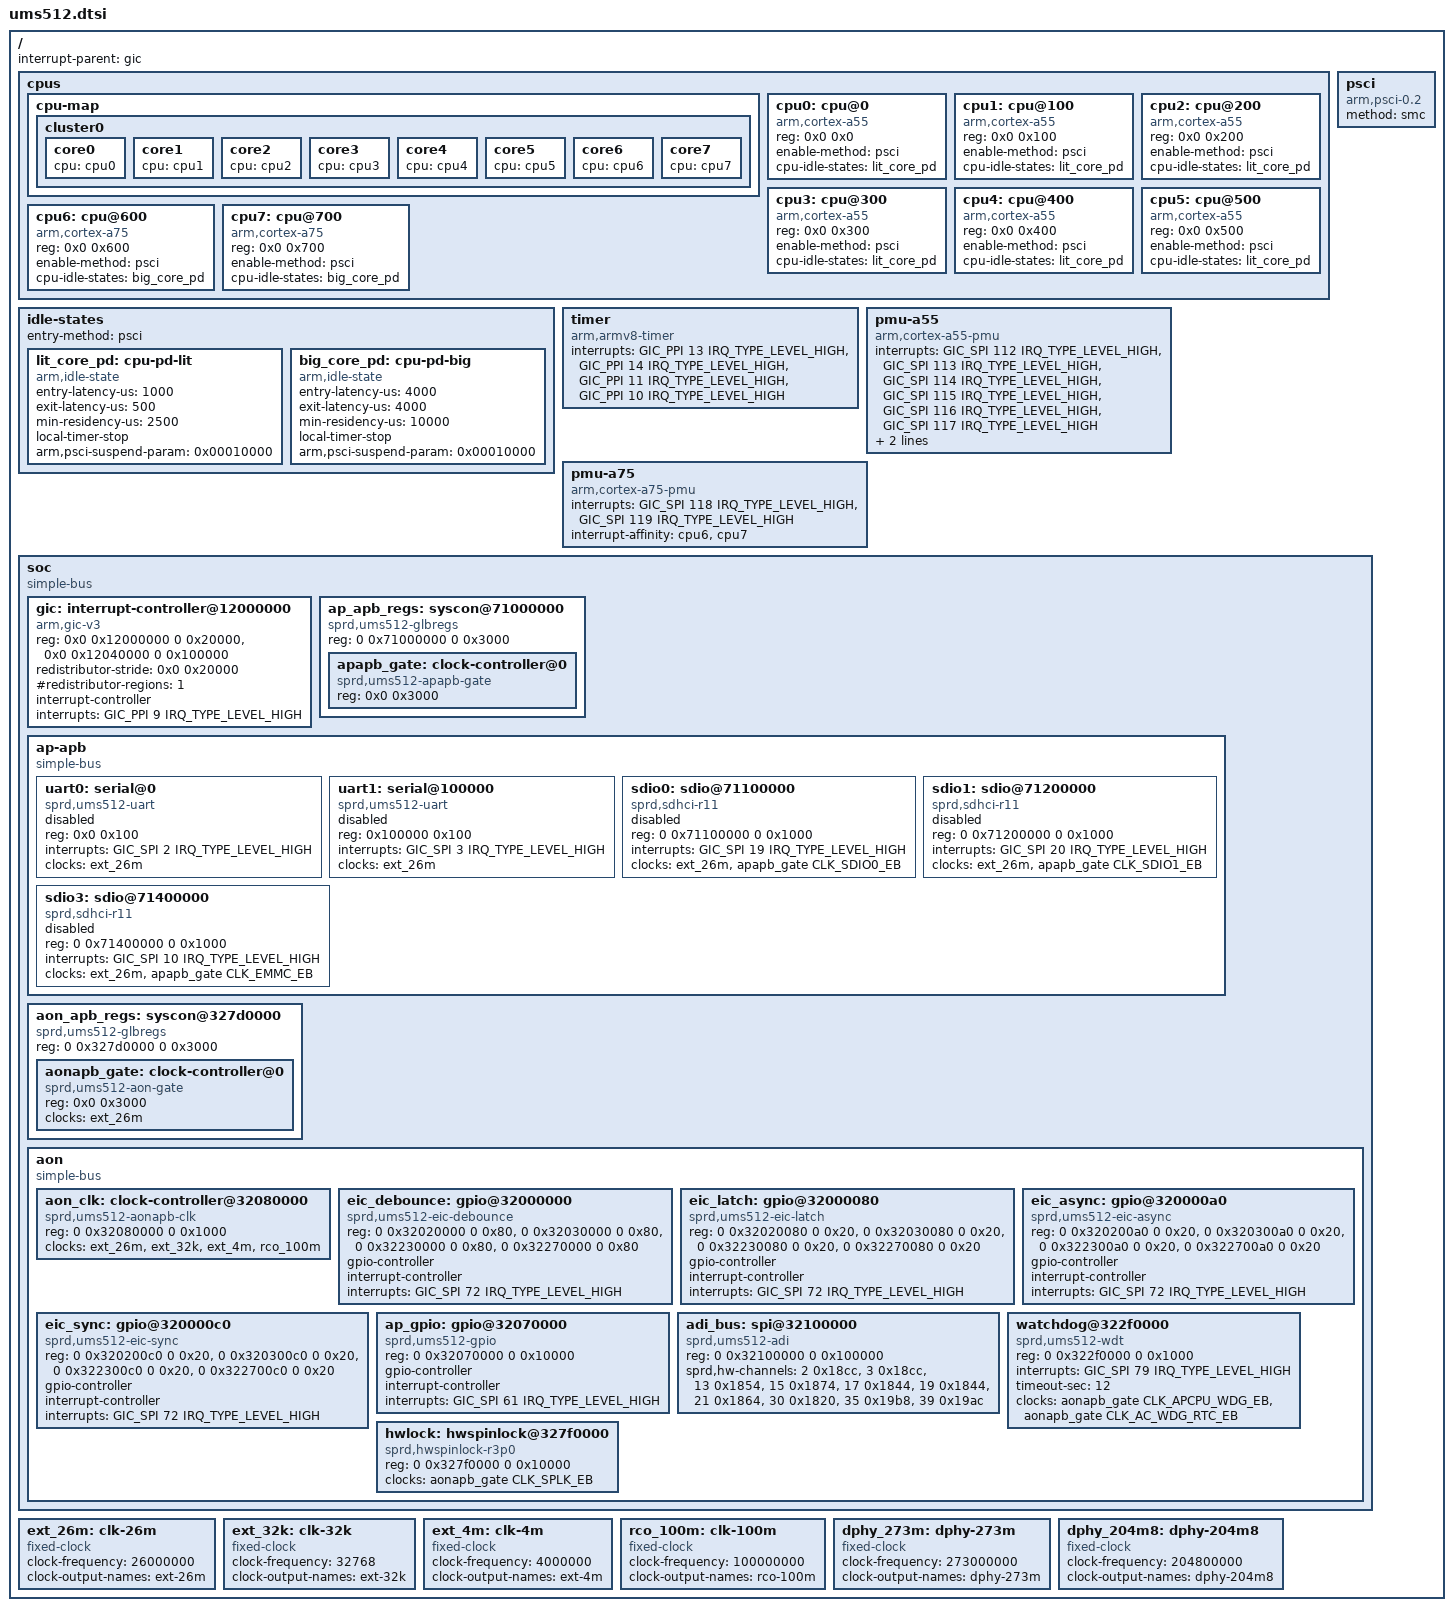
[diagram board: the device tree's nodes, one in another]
// SPDX-License-Identifier: (GPL-2.0 OR MIT)
/*
 * Unisoc UMS512 DTS file
 *
 * Copyright (C) 2025 Vladimir Panferov
 */

#include <dt-bindings/clock/sprd,ums512-clk.h>
#include <dt-bindings/gpio/gpio.h>
#include <dt-bindings/interrupt-controller/arm-gic.h>

/ {
	interrupt-parent = <&gic>;
	#address-cells = <2>;
	#size-cells = <2>;

	cpus {
		#address-cells = <2>;
		#size-cells = <0>;

		cpu-map {
			cluster0 {
				core0 {
					cpu = <&cpu0>;
				};
				core1 {
					cpu = <&cpu1>;
				};
				core2 {
					cpu = <&cpu2>;
				};
				core3 {
					cpu = <&cpu3>;
				};
				core4 {
					cpu = <&cpu4>;
				};
				core5 {
					cpu = <&cpu5>;
				};
				core6 {
					cpu = <&cpu6>;
				};
				core7 {
					cpu = <&cpu7>;
				};
			};
		};

		cpu0: cpu@0 {
			device_type = "cpu";
			compatible = "arm,cortex-a55";
			reg = <0x0 0x0>;
			enable-method = "psci";
			cpu-idle-states = <&lit_core_pd>;
		};

		cpu1: cpu@100 {
			device_type = "cpu";
			compatible = "arm,cortex-a55";
			reg = <0x0 0x100>;
			enable-method = "psci";
			cpu-idle-states = <&lit_core_pd>;
		};

		cpu2: cpu@200 {
			device_type = "cpu";
			compatible = "arm,cortex-a55";
			reg = <0x0 0x200>;
			enable-method = "psci";
			cpu-idle-states = <&lit_core_pd>;
		};

		cpu3: cpu@300 {
			device_type = "cpu";
			compatible = "arm,cortex-a55";
			reg = <0x0 0x300>;
			enable-method = "psci";
			cpu-idle-states = <&lit_core_pd>;
		};

		cpu4: cpu@400 {
			device_type = "cpu";
			compatible = "arm,cortex-a55";
			reg = <0x0 0x400>;
			enable-method = "psci";
			cpu-idle-states = <&lit_core_pd>;
		};

		cpu5: cpu@500 {
			device_type = "cpu";
			compatible = "arm,cortex-a55";
			reg = <0x0 0x500>;
			enable-method = "psci";
			cpu-idle-states = <&lit_core_pd>;
		};

		cpu6: cpu@600 {
			device_type = "cpu";
			compatible = "arm,cortex-a75";
			reg = <0x0 0x600>;
			enable-method = "psci";
			cpu-idle-states = <&big_core_pd>;
		};

		cpu7: cpu@700 {
			device_type = "cpu";
			compatible = "arm,cortex-a75";
			reg = <0x0 0x700>;
			enable-method = "psci";
			cpu-idle-states = <&big_core_pd>;
		};
	};

	idle-states {
		entry-method = "psci";
		lit_core_pd: cpu-pd-lit {
			compatible = "arm,idle-state";
			entry-latency-us = <1000>;
			exit-latency-us = <500>;
			min-residency-us = <2500>;
			local-timer-stop;
			arm,psci-suspend-param = <0x00010000>;
		};

		big_core_pd: cpu-pd-big {
			compatible = "arm,idle-state";
			entry-latency-us = <4000>;
			exit-latency-us = <4000>;
			min-residency-us = <10000>;
			local-timer-stop;
			arm,psci-suspend-param = <0x00010000>;
		};
	};

	psci {
		compatible = "arm,psci-0.2";
		method = "smc";
	};

	timer {
		compatible = "arm,armv8-timer";
		interrupts = <GIC_PPI 13 IRQ_TYPE_LEVEL_HIGH>, /* Physical Secure PPI */
			     <GIC_PPI 14 IRQ_TYPE_LEVEL_HIGH>, /* Physical Non-Secure PPI */
			     <GIC_PPI 11 IRQ_TYPE_LEVEL_HIGH>, /* Virtual PPI */
			     <GIC_PPI 10 IRQ_TYPE_LEVEL_HIGH>; /* Hipervisor PPI */
	};

	pmu-a55 {
		compatible = "arm,cortex-a55-pmu";
		interrupts = <GIC_SPI 112 IRQ_TYPE_LEVEL_HIGH>,
			     <GIC_SPI 113 IRQ_TYPE_LEVEL_HIGH>,
			     <GIC_SPI 114 IRQ_TYPE_LEVEL_HIGH>,
			     <GIC_SPI 115 IRQ_TYPE_LEVEL_HIGH>,
			     <GIC_SPI 116 IRQ_TYPE_LEVEL_HIGH>,
			     <GIC_SPI 117 IRQ_TYPE_LEVEL_HIGH>;
		interrupt-affinity = <&cpu0>, <&cpu1>, <&cpu2>, <&cpu3>, <&cpu4>, <&cpu5>;
	};

	pmu-a75 {
		compatible = "arm,cortex-a75-pmu";
		interrupts = <GIC_SPI 118 IRQ_TYPE_LEVEL_HIGH>,
			     <GIC_SPI 119 IRQ_TYPE_LEVEL_HIGH>;
		interrupt-affinity = <&cpu6>, <&cpu7>;
	};

	soc: soc {
		compatible = "simple-bus";
		ranges;
		#address-cells = <2>;
		#size-cells = <2>;

		gic: interrupt-controller@12000000 {
			compatible = "arm,gic-v3";
			reg = <0x0 0x12000000 0 0x20000>,	/* GICD */
			      <0x0 0x12040000 0 0x100000>;	/* GICR */
			#interrupt-cells = <3>;
			#address-cells = <2>;
			#size-cells = <2>;
			redistributor-stride = <0x0 0x20000>;	/* 128KB stride */
			#redistributor-regions = <1>;
			interrupt-controller;
			interrupts = <GIC_PPI 9 IRQ_TYPE_LEVEL_HIGH>;
		};

		ap_apb_regs: syscon@71000000 {
			compatible = "sprd,ums512-glbregs", "syscon", "simple-mfd";
			reg = <0 0x71000000 0 0x3000>;
			#address-cells = <1>;
			#size-cells = <1>;
			ranges = <0 0 0x71000000 0x3000>;

			apapb_gate: clock-controller@0 {
				compatible = "sprd,ums512-apapb-gate";
				reg = <0x0 0x3000>;
				#clock-cells = <1>;
			};
		};

		ap-apb {
			compatible = "simple-bus";
			#address-cells = <2>;
			#size-cells = <2>;
			ranges;

			uart0: serial@0 {
				compatible = "sprd,ums512-uart",
					     "sprd,sc9836-uart";
				reg = <0x0 0x100>;
				interrupts = <GIC_SPI 2 IRQ_TYPE_LEVEL_HIGH>;
				clocks = <&ext_26m>;
				status = "disabled";
			};

			uart1: serial@100000 {
				compatible = "sprd,ums512-uart",
					     "sprd,sc9836-uart";
				reg = <0x100000 0x100>;
				interrupts = <GIC_SPI 3 IRQ_TYPE_LEVEL_HIGH>;
				clocks = <&ext_26m>;
				status = "disabled";
			};

			sdio0: sdio@71100000 {
				compatible = "sprd,sdhci-r11";
				reg = <0 0x71100000 0 0x1000>;
				interrupts = <GIC_SPI 19 IRQ_TYPE_LEVEL_HIGH>;
				clocks = <&ext_26m>, <&apapb_gate CLK_SDIO0_EB>;
				clock-names = "sdio", "enable";
				status = "disabled";
			};

			sdio1: sdio@71200000 {
				compatible = "sprd,sdhci-r11";
				reg = <0 0x71200000 0 0x1000>;
				interrupts = <GIC_SPI 20 IRQ_TYPE_LEVEL_HIGH>;
				clocks = <&ext_26m>, <&apapb_gate CLK_SDIO1_EB>;
				clock-names = "sdio", "enable";
				status = "disabled";
			};

			sdio3: sdio@71400000 {
				compatible = "sprd,sdhci-r11";
				reg = <0 0x71400000 0 0x1000>;
				interrupts = <GIC_SPI 10 IRQ_TYPE_LEVEL_HIGH>;
				clocks = <&ext_26m>, <&apapb_gate CLK_EMMC_EB>;
				clock-names = "sdio", "enable";
				status = "disabled";
			};
		};

		aon_apb_regs: syscon@327d0000 {
			compatible = "sprd,ums512-glbregs", "syscon",
				     "simple-mfd";
			reg = <0 0x327d0000 0 0x3000>;
			#address-cells = <1>;
			#size-cells = <1>;
			ranges = <0 0 0x327d0000 0x3000>;

			aonapb_gate: clock-controller@0 {
				compatible = "sprd,ums512-aon-gate";
				reg = <0x0 0x3000>;
				clocks = <&ext_26m>;
				clock-names = "ext-26m";
				#clock-cells = <1>;
				#reset-cells = <1>;
			};
		};

		aon {
			compatible = "simple-bus";
			#address-cells = <2>;
			#size-cells = <2>;
			ranges;

			aon_clk: clock-controller@32080000 {
				compatible = "sprd,ums512-aonapb-clk";
				reg = <0 0x32080000 0 0x1000>;
				clocks = <&ext_26m>, <&ext_32k>,
					 <&ext_4m>, <&rco_100m>;
				clock-names = "ext-26m", "ext-32k",
					      "ext-4m", "rco-100m";
				#clock-cells = <1>;
			};

			eic_debounce: gpio@32000000 {
				compatible = "sprd,ums512-eic-debounce", "sprd,sc9860-eic-debounce";
				reg = <0 0x32020000 0 0x80>,
				      <0 0x32030000 0 0x80>,
				      <0 0x32230000 0 0x80>,
				      <0 0x32270000 0 0x80>;
				gpio-controller;
				#gpio-cells = <2>;
				interrupt-controller;
				#interrupt-cells = <2>;
				interrupts = <GIC_SPI 72 IRQ_TYPE_LEVEL_HIGH>;
			};

			eic_latch: gpio@32000080 {
				compatible = "sprd,ums512-eic-latch", "sprd,sc9860-eic-latch";
				reg = <0 0x32020080 0 0x20>,
				      <0 0x32030080 0 0x20>,
				      <0 0x32230080 0 0x20>,
				      <0 0x32270080 0 0x20>;
				gpio-controller;
				#gpio-cells = <2>;
				interrupt-controller;
				#interrupt-cells = <2>;
				interrupts = <GIC_SPI 72 IRQ_TYPE_LEVEL_HIGH>;
			};

			eic_async: gpio@320000a0 {
				compatible = "sprd,ums512-eic-async", "sprd,sc9860-eic-async";
				reg = <0 0x320200a0 0 0x20>,
				      <0 0x320300a0 0 0x20>,
				      <0 0x322300a0 0 0x20>,
				      <0 0x322700a0 0 0x20>;
				gpio-controller;
				#gpio-cells = <2>;
				interrupt-controller;
				#interrupt-cells = <2>;
				interrupts = <GIC_SPI 72 IRQ_TYPE_LEVEL_HIGH>;
			};

			eic_sync: gpio@320000c0 {
				compatible = "sprd,ums512-eic-sync", "sprd,sc9860-eic-sync";
				reg = <0 0x320200c0 0 0x20>,
				      <0 0x320300c0 0 0x20>,
				      <0 0x322300c0 0 0x20>,
				      <0 0x322700c0 0 0x20>;
				gpio-controller;
				#gpio-cells = <2>;
				interrupt-controller;
				#interrupt-cells = <2>;
				interrupts = <GIC_SPI 72 IRQ_TYPE_LEVEL_HIGH>;
			};

			ap_gpio: gpio@32070000 {
				compatible = "sprd,ums512-gpio", "sprd,sc9860-gpio";
				reg = <0 0x32070000 0 0x10000>;
				gpio-controller;
				#gpio-cells = <2>;
				interrupt-controller;
				#interrupt-cells = <2>;
				interrupts = <GIC_SPI 61 IRQ_TYPE_LEVEL_HIGH>;
			};

			adi_bus: spi@32100000 {
				compatible = "sprd,ums512-adi";
				reg = <0 0x32100000 0 0x100000>;
				#address-cells = <1>;
				#size-cells = <0>;
				sprd,hw-channels = <2 0x18cc>, <3 0x18cc>, <13 0x1854>, <15 0x1874>,
					<17 0x1844>,<19 0x1844>, <21 0x1864>, <30 0x1820>,
					<35 0x19b8>, <39 0x19ac>;
			};

			watchdog@322f0000 {
				compatible = "sprd,ums512-wdt", "sprd,sp9860-wdt";
				reg = <0 0x322f0000 0 0x1000>;
				interrupts = <GIC_SPI 79 IRQ_TYPE_LEVEL_HIGH>;
				timeout-sec = <12>;
				clocks = <&aonapb_gate CLK_APCPU_WDG_EB>,
		   	    <&aonapb_gate CLK_AC_WDG_RTC_EB>;
				clock-names = "enable", "rtc_enable";
			};

			hwlock: hwspinlock@327f0000 {
				compatible = "sprd,hwspinlock-r3p0";
				reg = <0 0x327f0000 0 0x10000>;
				#hwlock-cells = <1>;
				clocks = <&aonapb_gate CLK_SPLK_EB>;
				clock-names = "enable";
			};
		};
	};

	ext_26m: clk-26m {
		compatible = "fixed-clock";
		#clock-cells = <0>;
		clock-frequency = <26000000>;
		clock-output-names = "ext-26m";
	};

	ext_32k: clk-32k {
		compatible = "fixed-clock";
		#clock-cells = <0>;
		clock-frequency = <32768>;
		clock-output-names = "ext-32k";
	};

	ext_4m: clk-4m {
		compatible = "fixed-clock";
		#clock-cells = <0>;
		clock-frequency = <4000000>;
		clock-output-names = "ext-4m";
	};

	rco_100m: clk-100m {
		compatible = "fixed-clock";
		#clock-cells = <0>;
		clock-frequency = <100000000>;
		clock-output-names = "rco-100m";
	};

	dphy_273m: dphy-273m {
		compatible = "fixed-clock";
		#clock-cells = <0>;
		clock-frequency = <273000000>;
		clock-output-names = "dphy-273m";
	};

	dphy_204m8: dphy-204m8 {
		compatible = "fixed-clock";
		#clock-cells = <0>;
		clock-frequency = <204800000>;
		clock-output-names = "dphy-204m8";
	};
};
